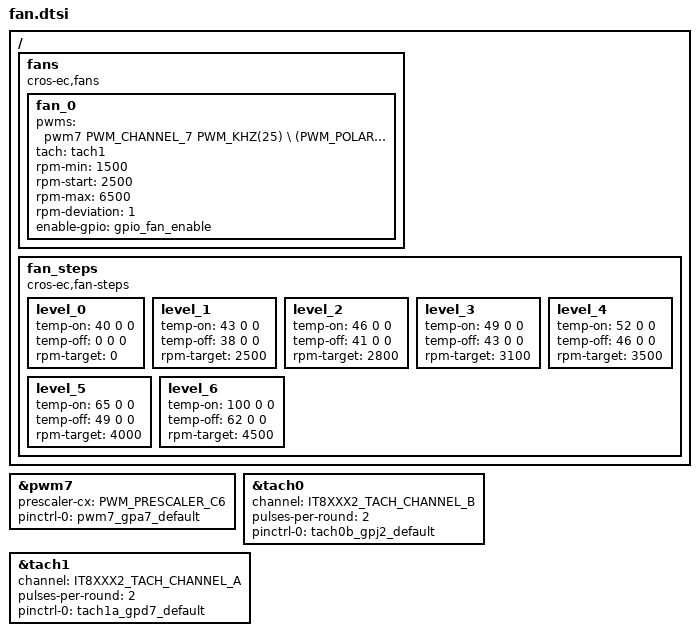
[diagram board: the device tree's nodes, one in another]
/* Copyright 2023 The ChromiumOS Authors
 * Use of this source code is governed by a BSD-style license that can be
 * found in the LICENSE file.
 */
/ {
	fans {
		compatible = "cros-ec,fans";
		fan_0 {
			pwms = <&pwm7 PWM_CHANNEL_7 PWM_KHZ(25) \
				(PWM_POLARITY_NORMAL | PWM_IT8XXX2_OPEN_DRAIN)>;
			tach = <&tach1>;
			rpm-min = <1500>;
			rpm-start = <2500>;
			rpm-max = <6500>;
			rpm-deviation = <1>;
			enable-gpio = <&gpio_fan_enable>;
		};
	};
	fan_steps {
		compatible = "cros-ec,fan-steps";
		level_0 {
			temp-on = <40 0 0>;
			temp-off = <0 0 0>;
			rpm-target = <0>;
		};
		level_1 {
			temp-on = <43 0 0>;
			temp-off = <38 0 0>;
			rpm-target = <2500>;
		};
		level_2 {
			temp-on = <46 0 0>;
			temp-off = <41 0 0>;
			rpm-target = <2800>;
		};
		level_3 {
			temp-on = <49 0 0>;
			temp-off = <43 0 0>;
			rpm-target = <3100>;
		};
		level_4 {
			temp-on = <52 0 0>;
			temp-off = <46 0 0>;
			rpm-target = <3500>;
		};
		level_5 {
			temp-on = <65 0 0>;
			temp-off = <49 0 0>;
			rpm-target = <4000>;
		};
		level_6 {
			temp-on = <100 0 0>;
			temp-off = <62 0 0>;
			rpm-target = <4500>;
		};
	};
};

/* pwm for fan */
&pwm7 {
	status = "okay";
	prescaler-cx = <PWM_PRESCALER_C6>;
	pinctrl-0 = <&pwm7_gpa7_default>;
	pinctrl-names = "default";
};

/* fan tachometer sensor */
&tach0 {
	status = "okay";
	channel = <IT8XXX2_TACH_CHANNEL_B>;
	pulses-per-round = <2>;
	pinctrl-0 = <&tach0b_gpj2_default>;
	pinctrl-names = "default";
};

&tach1 {
	status = "okay";
	channel = <IT8XXX2_TACH_CHANNEL_A>;
	pulses-per-round = <2>;
	pinctrl-0 = <&tach1a_gpd7_default>;
	pinctrl-names = "default";
};
